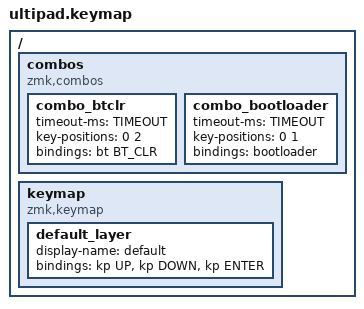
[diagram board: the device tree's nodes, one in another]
/*
 * Copyright (c) 2021 The ZMK Contributors
 *
 * SPDX-License-Identifier: MIT
 */

#include <behaviors.dtsi>
#include <dt-bindings/zmk/keys.h>
#include <dt-bindings/zmk/bt.h>

#define TIMEOUT 300

/ {
    combos {
        compatible = "zmk,combos";
        combo_btclr {
            timeout-ms = <TIMEOUT>;
            key-positions = <0 2>;
            bindings = <&bt BT_CLR>;
        };
        combo_bootloader {
            timeout-ms = <TIMEOUT>;
            key-positions = <0 1>;
            bindings = <&bootloader>;
        };
    };

    keymap: keymap {
        compatible = "zmk,keymap";

        default_layer {
            display-name = "default";
            bindings = <
                &kp UP
                &kp DOWN
                &kp ENTER
            >;
        };
    };
};
